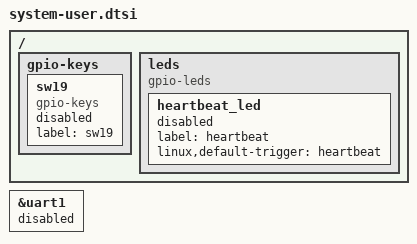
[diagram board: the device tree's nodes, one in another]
/include/ "system-conf.dtsi"
/ {
gpio-keys {
 sw19 {
 	compatible = "gpio-keys";
 	label = "sw19";
 	status = "disabled";
 	};
 };
 leds {
 compatible = "gpio-leds";
 heartbeat_led {
 label = "heartbeat";
 linux,default-trigger = "heartbeat";
 status = "disabled";
 };
 };
};
&uart1
{
 status = "disabled";
};
